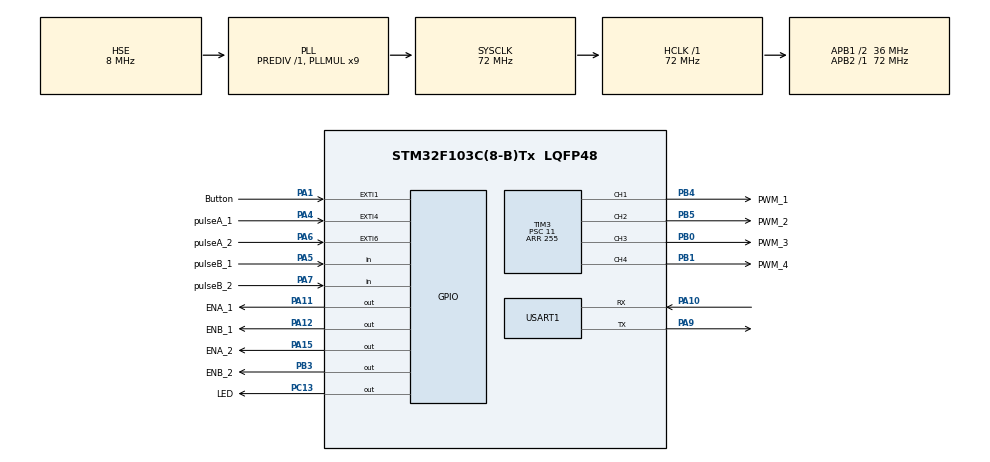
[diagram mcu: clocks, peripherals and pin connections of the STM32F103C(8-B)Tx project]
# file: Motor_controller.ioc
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Mcu.Family=STM32F1
Mcu.Name=STM32F103C(8-B)Tx
Mcu.Package=LQFP48
NVIC.EXTI1_IRQn=true\:5\:0\:true\:false\:true\:true\:true\:true
NVIC.EXTI4_IRQn=true\:5\:0\:true\:false\:true\:true\:true\:true
NVIC.EXTI9_5_IRQn=true\:5\:0\:true\:false\:true\:true\:true\:true
NVIC.PriorityGroup=NVIC_PRIORITYGROUP_4
NVIC.TIM2_IRQn=true\:4\:0\:true\:false\:true\:true\:true\:true
NVIC.TIM3_IRQn=true\:4\:0\:true\:false\:true\:true\:true\:true
NVIC.USART1_IRQn=true\:2\:0\:true\:false\:true\:true\:true\:true
PA1.GPIO_Label=Button
PA1.GPIO_PuPd=GPIO_PULLDOWN
PA1.Signal=GPXTI1
PA10.Mode=Asynchronous
PA10.Signal=USART1_RX
PA11.GPIO_Label=ENA_1
PA11.Signal=GPIO_Output
PA12.GPIO_Label=ENB_1
PA12.Signal=GPIO_Output
PA13.Mode=Serial_Wire
PA13.Signal=SYS_JTMS-SWDIO
PA14.Mode=Serial_Wire
PA14.Signal=SYS_JTCK-SWCLK
PA15.GPIO_Label=ENA_2
PA15.Signal=GPIO_Output
PA4.GPIO_Label=pulseA_1
PA4.Signal=GPXTI4
PA5.GPIO_Label=pulseB_1
PA5.Signal=GPIO_Input
PA6.GPIO_Label=pulseA_2
PA6.Signal=GPXTI6
PA7.GPIO_Label=pulseB_2
PA7.Signal=GPIO_Input
PA9.Mode=Asynchronous
PA9.Signal=USART1_TX
PB0.GPIO_Label=PWM_3
PB0.Signal=S_TIM3_CH3
PB1.GPIO_Label=PWM_4
PB1.Signal=S_TIM3_CH4
PB3.GPIO_Label=ENB_2
PB3.Signal=GPIO_Output
PB4.GPIO_Label=PWM_1
PB4.Signal=S_TIM3_CH1
PB5.GPIO_Label=PWM_2
PB5.Signal=S_TIM3_CH2
PC13-TAMPER-RTC.GPIO_Label=LED
PC13-TAMPER-RTC.Signal=GPIO_Output
PD0-OSC_IN.Mode=HSE-External-Oscillator
PD0-OSC_IN.Signal=RCC_OSC_IN
PD1-OSC_OUT.Mode=HSE-External-Oscillator
PD1-OSC_OUT.Signal=RCC_OSC_OUT
ProjectManager.HeapSize=0x200
ProjectManager.StackSize=0x400
ProjectManager.TargetToolchain=MDK-ARM V5.32
RCC.AHBFreq_Value=72000000
RCC.APB1CLKDivider=RCC_HCLK_DIV2
RCC.APB1Freq_Value=36000000
RCC.APB1TimFreq_Value=72000000
RCC.APB2Freq_Value=72000000
RCC.APB2TimFreq_Value=72000000
RCC.HCLKFreq_Value=72000000
RCC.PLLMUL=RCC_PLL_MUL9
RCC.PLLSourceVirtual=RCC_PLLSOURCE_HSE
RCC.SYSCLKFreq_VALUE=72000000
RCC.SYSCLKSource=RCC_SYSCLKSOURCE_PLLCLK
RCC.USBFreq_Value=72000000
SH.S_TIM3_CH1.0=TIM3_CH1,PWM Generation1 CH1
SH.S_TIM3_CH2.0=TIM3_CH2,PWM Generation2 CH2
SH.S_TIM3_CH3.0=TIM3_CH3,PWM Generation3 CH3
SH.S_TIM3_CH4.0=TIM3_CH4,PWM Generation4 CH4
TIM2.AutoReloadPreload=TIM_AUTORELOAD_PRELOAD_ENABLE
TIM2.Period=9999
TIM2.Prescaler=719
TIM3.Channel-PWM\ Generation1\ CH1=TIM_CHANNEL_1
TIM3.Channel-PWM\ Generation2\ CH2=TIM_CHANNEL_2
TIM3.Channel-PWM\ Generation3\ CH3=TIM_CHANNEL_3
TIM3.Channel-PWM\ Generation4\ CH4=TIM_CHANNEL_4
TIM3.Period=255
TIM3.Prescaler=11
USART1.VirtualMode=VM_ASYNC
VP_TIM2_VS_ClockSourceINT.Mode=Internal
VP_TIM3_VS_ClockSourceINT.Mode=Internal
board=custom

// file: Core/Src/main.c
/* USER CODE BEGIN Header */
/**
  ******************************************************************************
  * @file           : main.c
  * @brief          : Main program body
  ******************************************************************************
  * @attention
  *
  * Copyright (c) 2023 STMicroelectronics.
  * All rights reserved.
  *1

  * This software is licensed under terms that can be found in the LICENSE file
  * in the root directory of this software component.
  * If no LICENSE file comes with this software, it is provided AS-IS.
  *
  ******************************************************************************
  */
/* USER CODE END Header */
#include "main.h"
#include <stdio.h>
#include <string.h>
#include <stdlib.h>

# define M_PI           3.14159265358979323846

TIM_HandleTypeDef htim2;
TIM_HandleTypeDef htim3;

UART_HandleTypeDef huart1;

float vel_fb[2] = {0, 0};
float vel[2] = {10, 10};
uint8_t te  = 2;
uint8_t pwm[4] = {0, 0, 0, 0};
uint32_t elapsedtime;
uint32_t current_time_in_100ms = 0;
uint32_t current_time_in_us[2] = {0, 0};
uint32_t last_time_in_100ms[2] = {0, 0};
uint32_t last_time_in_us[2] = {0, 0};

//uint8_t data[3] = {1,2,3};
//uint8_t data[] = "Hello, UART!\r\n";
float a =1.2;

TIM_HandleTypeDef htim2;
TIM_HandleTypeDef htim3;

UART_HandleTypeDef huart1;

void SystemClock_Config(void);
static void MX_GPIO_Init(void);
static void MX_USART1_UART_Init(void);
static void MX_TIM2_Init(void);
static void MX_TIM3_Init(void);

int main(void)
{

  /* MCU Configuration--------------------------------------------------------*/

  /* Reset of all peripherals, Initializes the Flash interface and the Systick. */
  HAL_Init();

  /* Configure the system clock */
  SystemClock_Config();

  /* Initialize all configured peripherals */
  MX_GPIO_Init();
  MX_USART1_UART_Init();
  MX_TIM2_Init();
  MX_TIM3_Init();
  /* USER CODE BEGIN 2 */
		HAL_UART_Receive_IT(&huart1, pwm, sizeof(pwm));
		HAL_TIM_Base_Start_IT(&htim2);
		HAL_TIM_Base_Start(&htim3);
		HAL_TIM_PWM_Start(&htim3, TIM_CHANNEL_1);
		HAL_TIM_PWM_Start(&htim3, TIM_CHANNEL_2);
		HAL_TIM_PWM_Start(&htim3, TIM_CHANNEL_3);
		HAL_TIM_PWM_Start(&htim3, TIM_CHANNEL_4);

		__HAL_TIM_SetCompare(&htim3, TIM_CHANNEL_1, 0);
		__HAL_TIM_SetCompare(&htim3, TIM_CHANNEL_2, 0);
		__HAL_TIM_SetCompare(&htim3, TIM_CHANNEL_3, 0);
		__HAL_TIM_SetCompare(&htim3, TIM_CHANNEL_4, 0);
  /* USER CODE END 2 */

  /* Infinite loop */
  while (1)
  {

  }
}

void SystemClock_Config(void)
{
  RCC_OscInitTypeDef RCC_OscInitStruct = {0};
  RCC_ClkInitTypeDef RCC_ClkInitStruct = {0};

  /** Initializes the RCC Oscillators according to the specified parameters
  * in the RCC_OscInitTypeDef structure.
  */
  RCC_OscInitStruct.OscillatorType = RCC_OSCILLATORTYPE_HSE;
  RCC_OscInitStruct.HSEState = RCC_HSE_ON;
  RCC_OscInitStruct.HSEPredivValue = RCC_HSE_PREDIV_DIV1;
  RCC_OscInitStruct.HSIState = RCC_HSI_ON;
  RCC_OscInitStruct.PLL.PLLState = RCC_PLL_ON;
  RCC_OscInitStruct.PLL.PLLSource = RCC_PLLSOURCE_HSE;
  RCC_OscInitStruct.PLL.PLLMUL = RCC_PLL_MUL9;
  if (HAL_RCC_OscConfig(&RCC_OscInitStruct) != HAL_OK)
  {
    Error_Handler();
  }

  /** Initializes the CPU, AHB and APB buses clocks
  */
  RCC_ClkInitStruct.ClockType = RCC_CLOCKTYPE_HCLK|RCC_CLOCKTYPE_SYSCLK
                              |RCC_CLOCKTYPE_PCLK1|RCC_CLOCKTYPE_PCLK2;
  RCC_ClkInitStruct.SYSCLKSource = RCC_SYSCLKSOURCE_PLLCLK;
  RCC_ClkInitStruct.AHBCLKDivider = RCC_SYSCLK_DIV1;
  RCC_ClkInitStruct.APB1CLKDivider = RCC_HCLK_DIV2;
  RCC_ClkInitStruct.APB2CLKDivider = RCC_HCLK_DIV1;

  if (HAL_RCC_ClockConfig(&RCC_ClkInitStruct, FLASH_LATENCY_2) != HAL_OK)
  {
    Error_Handler();
  }
}

static void MX_TIM2_Init(void)
{

  TIM_ClockConfigTypeDef sClockSourceConfig = {0};
  TIM_MasterConfigTypeDef sMasterConfig = {0};

  htim2.Instance = TIM2;
  htim2.Init.Prescaler = 719;
  htim2.Init.CounterMode = TIM_COUNTERMODE_UP;
  htim2.Init.Period = 9999;
  htim2.Init.ClockDivision = TIM_CLOCKDIVISION_DIV1;
  htim2.Init.AutoReloadPreload = TIM_AUTORELOAD_PRELOAD_ENABLE;
  if (HAL_TIM_Base_Init(&htim2) != HAL_OK)
  {
    Error_Handler();
  }
  sClockSourceConfig.ClockSource = TIM_CLOCKSOURCE_INTERNAL;
  if (HAL_TIM_ConfigClockSource(&htim2, &sClockSourceConfig) != HAL_OK)
  {
    Error_Handler();
  }
  sMasterConfig.MasterOutputTrigger = TIM_TRGO_RESET;
  sMasterConfig.MasterSlaveMode = TIM_MASTERSLAVEMODE_DISABLE;
  if (HAL_TIMEx_MasterConfigSynchronization(&htim2, &sMasterConfig) != HAL_OK)
  {
    Error_Handler();
  }

}

static void MX_TIM3_Init(void)
{

  TIM_ClockConfigTypeDef sClockSourceConfig = {0};
  TIM_MasterConfigTypeDef sMasterConfig = {0};
  TIM_OC_InitTypeDef sConfigOC = {0};

  htim3.Instance = TIM3;
  htim3.Init.Prescaler = 11;
  htim3.Init.CounterMode = TIM_COUNTERMODE_UP;
  htim3.Init.Period = 255;
  htim3.Init.ClockDivision = TIM_CLOCKDIVISION_DIV1;
  htim3.Init.AutoReloadPreload = TIM_AUTORELOAD_PRELOAD_DISABLE;
  if (HAL_TIM_Base_Init(&htim3) != HAL_OK)
  {
    Error_Handler();
  }
  sClockSourceConfig.ClockSource = TIM_CLOCKSOURCE_INTERNAL;
  if (HAL_TIM_ConfigClockSource(&htim3, &sClockSourceConfig) != HAL_OK)
  {
    Error_Handler();
  }
  if (HAL_TIM_PWM_Init(&htim3) != HAL_OK)
  {
    Error_Handler();
  }
  sMasterConfig.MasterOutputTrigger = TIM_TRGO_RESET;
  sMasterConfig.MasterSlaveMode = TIM_MASTERSLAVEMODE_DISABLE;
  if (HAL_TIMEx_MasterConfigSynchronization(&htim3, &sMasterConfig) != HAL_OK)
  {
    Error_Handler();
  }
  sConfigOC.OCMode = TIM_OCMODE_PWM1;
  sConfigOC.Pulse = 0;
  sConfigOC.OCPolarity = TIM_OCPOLARITY_HIGH;
  sConfigOC.OCFastMode = TIM_OCFAST_DISABLE;
  if (HAL_TIM_PWM_ConfigChannel(&htim3, &sConfigOC, TIM_CHANNEL_1) != HAL_OK)
  {
    Error_Handler();
  }
  if (HAL_TIM_PWM_ConfigChannel(&htim3, &sConfigOC, TIM_CHANNEL_2) != HAL_OK)
  {
    Error_Handler();
  }
  if (HAL_TIM_PWM_ConfigChannel(&htim3, &sConfigOC, TIM_CHANNEL_3) != HAL_OK)
  {
    Error_Handler();
  }
  if (HAL_TIM_PWM_ConfigChannel(&htim3, &sConfigOC, TIM_CHANNEL_4) != HAL_OK)
  {
    Error_Handler();
  }
  HAL_TIM_MspPostInit(&htim3);

}

static void MX_USART1_UART_Init(void)
{

  huart1.Instance = USART1;
  huart1.Init.BaudRate = 115200;
  huart1.Init.WordLength = UART_WORDLENGTH_8B;
  huart1.Init.StopBits = UART_STOPBITS_1;
  huart1.Init.Parity = UART_PARITY_NONE;
  huart1.Init.Mode = UART_MODE_TX_RX;
  huart1.Init.HwFlowCtl = UART_HWCONTROL_NONE;
  huart1.Init.OverSampling = UART_OVERSAMPLING_16;
  if (HAL_UART_Init(&huart1) != HAL_OK)
  {
    Error_Handler();
  }

}

static void MX_GPIO_Init(void)
{
  GPIO_InitTypeDef GPIO_InitStruct = {0};

  /* GPIO Ports Clock Enable */
  __HAL_RCC_GPIOC_CLK_ENABLE();
  __HAL_RCC_GPIOD_CLK_ENABLE();
  __HAL_RCC_GPIOA_CLK_ENABLE();
  __HAL_RCC_GPIOB_CLK_ENABLE();

  /*Configure GPIO pin Output Level */
  HAL_GPIO_WritePin(LED_GPIO_Port, LED_Pin, GPIO_PIN_RESET);

  /*Configure GPIO pin Output Level */
  HAL_GPIO_WritePin(GPIOA, ENA_1_Pin|ENB_1_Pin|ENA_2_Pin, GPIO_PIN_RESET);

  /*Configure GPIO pin Output Level */
  HAL_GPIO_WritePin(ENB_2_GPIO_Port, ENB_2_Pin, GPIO_PIN_RESET);

  /*Configure GPIO pin : LED_Pin */
  GPIO_InitStruct.Pin = LED_Pin;
  GPIO_InitStruct.Mode = GPIO_MODE_OUTPUT_PP;
  GPIO_InitStruct.Pull = GPIO_NOPULL;
  GPIO_InitStruct.Speed = GPIO_SPEED_FREQ_LOW;
  HAL_GPIO_Init(LED_GPIO_Port, &GPIO_InitStruct);

  /*Configure GPIO pin : Button_Pin */
  GPIO_InitStruct.Pin = Button_Pin;
  GPIO_InitStruct.Mode = GPIO_MODE_IT_RISING;
  GPIO_InitStruct.Pull = GPIO_PULLDOWN;
  HAL_GPIO_Init(Button_GPIO_Port, &GPIO_InitStruct);

  /*Configure GPIO pins : pulseA_1_Pin pulseA_2_Pin */
  GPIO_InitStruct.Pin = pulseA_1_Pin|pulseA_2_Pin;
  GPIO_InitStruct.Mode = GPIO_MODE_IT_RISING;
  GPIO_InitStruct.Pull = GPIO_NOPULL;
  HAL_GPIO_Init(GPIOA, &GPIO_InitStruct);

  /*Configure GPIO pins : pulseB_1_Pin pulseB_2_Pin */
  GPIO_InitStruct.Pin = pulseB_1_Pin|pulseB_2_Pin;
  GPIO_InitStruct.Mode = GPIO_MODE_INPUT;
  GPIO_InitStruct.Pull = GPIO_NOPULL;
  HAL_GPIO_Init(GPIOA, &GPIO_InitStruct);

  /*Configure GPIO pins : ENA_1_Pin ENB_1_Pin ENA_2_Pin */
  GPIO_InitStruct.Pin = ENA_1_Pin|ENB_1_Pin|ENA_2_Pin;
  GPIO_InitStruct.Mode = GPIO_MODE_OUTPUT_PP;
  GPIO_InitStruct.Pull = GPIO_NOPULL;
  GPIO_InitStruct.Speed = GPIO_SPEED_FREQ_LOW;
  HAL_GPIO_Init(GPIOA, &GPIO_InitStruct);

  /*Configure GPIO pin : ENB_2_Pin */
  GPIO_InitStruct.Pin = ENB_2_Pin;
  GPIO_InitStruct.Mode = GPIO_MODE_OUTPUT_PP;
  GPIO_InitStruct.Pull = GPIO_NOPULL;
  GPIO_InitStruct.Speed = GPIO_SPEED_FREQ_LOW;
  HAL_GPIO_Init(ENB_2_GPIO_Port, &GPIO_InitStruct);

  /* EXTI interrupt init*/
  HAL_NVIC_SetPriority(EXTI1_IRQn, 5, 0);
  HAL_NVIC_EnableIRQ(EXTI1_IRQn);

  HAL_NVIC_SetPriority(EXTI4_IRQn, 5, 0);
  HAL_NVIC_EnableIRQ(EXTI4_IRQn);

  HAL_NVIC_SetPriority(EXTI9_5_IRQn, 5, 0);
  HAL_NVIC_EnableIRQ(EXTI9_5_IRQn);

}

void send_velocity(char* Pos, float vel){
		float float_array[] = {1.2345, 4.56, 7.89};

    // Convert float array to char array (string)
    char char_array[50];  // Adjust the size based on your requirements
    int offset = 0;
		int i = 0;
		offset += snprintf(char_array + offset, sizeof(char_array) - offset, "%s%fe", Pos, vel);
    /*for (i = 1; i < sizeof(vel_fb) / sizeof(float) -1; i++) {
        offset += snprintf(char_array + offset, sizeof(char_array) - offset, "%f,", vel_fb[i]);
    }
		offset += snprintf(char_array + offset, sizeof(char_array) - offset, "%fe", vel_fb[i]);*/

    // Transmit data
    HAL_UART_Transmit(&huart1, (uint8_t*)char_array, strlen(char_array), HAL_MAX_DELAY);

		//HAL_Delay(1);

}

float calculate_velocity(GPIO_TypeDef *GPIOx, uint16_t GPIO_Pin, uint8_t pin)
{
	current_time_in_us[pin] = __HAL_TIM_GetCounter(&htim2);
	elapsedtime = (current_time_in_100ms - last_time_in_100ms[pin]) * 10000 + current_time_in_us[pin] - last_time_in_us[pin];
	last_time_in_100ms[pin] = current_time_in_100ms;
	last_time_in_us[pin] = current_time_in_us[pin];

	if (HAL_GPIO_ReadPin(GPIOx, GPIO_Pin) == 1)
	{
		vel_fb[pin] = 2*M_PI / 249.6 / elapsedtime * 100000 ;

	}
	else
	{
		vel_fb[pin] = -2*M_PI / 249.6 / elapsedtime * 100000 ;
	}
	return vel_fb[pin];
}

void HAL_GPIO_EXTI_Callback(uint16_t GPIO_Pin)
{
	float vel;
  if (GPIO_Pin == pulseA_1_Pin)
	{
		vel = calculate_velocity(pulseB_1_GPIO_Port, pulseB_1_Pin, 0);
		char* Pos ="L";
		send_velocity(Pos, vel);

	}
	else if (GPIO_Pin == pulseA_2_Pin)
	{
		vel = calculate_velocity(pulseB_2_GPIO_Port, pulseB_2_Pin, 1);
		char* Pos ="R";
		send_velocity(Pos, vel);
	}
}

void HAL_UART_RxCpltCallback(UART_HandleTypeDef *huart)
{
 if(huart->Instance == huart1.Instance)
 {
	 __HAL_TIM_SetCompare(&htim3, TIM_CHANNEL_1, pwm[0]);
	 __HAL_TIM_SetCompare(&htim3, TIM_CHANNEL_2, pwm[1]);
	 __HAL_TIM_SetCompare(&htim3, TIM_CHANNEL_3, pwm[2]);
	 __HAL_TIM_SetCompare(&htim3, TIM_CHANNEL_4, pwm[3]);
	 HAL_UART_Receive_IT(&huart1, pwm, sizeof(pwm));
 }
}

void HAL_TIM_PeriodElapsedCallback(TIM_HandleTypeDef *htim)
{
	current_time_in_100ms += 1;
//	if (current_time_in_100ms % 10 == 0) HAL_GPIO_TogglePin(GPIOC, GPIO_PIN_13);
}
void Error_Handler(void)
{
  __disable_irq();
  while (1)
  {
  }
}
